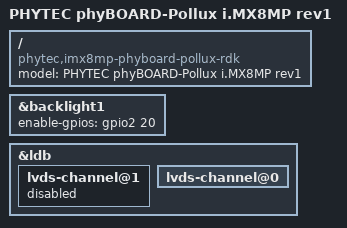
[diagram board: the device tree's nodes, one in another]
// SPDX-License-Identifier: GPL-2.0
/*
 * Copyright (C) 2021 PHYTEC Messtechnik GmbH
 * Author: Dominik Haller <d.haller@phytec.de>
 */

/dts-v1/;

#include "imx8mp-phycore-som.dtsi"
#include "imx8mp-phyboard-pollux.dtsi"
#include "imx8mp-phyboard-pollux-peb-wlbt-05.dtsi"

/ {
	model = "PHYTEC phyBOARD-Pollux i.MX8MP rev1";
	compatible = "phytec,imx8mp-phyboard-pollux-rdk",
		     "phytec,imx8mp-phycore-som", "fsl,imx8mp";
};

&backlight1 {
	enable-gpios = <&gpio2 20 GPIO_ACTIVE_HIGH>;
};

&ldb {
	lvds-channel@1 {
		status = "disabled";
	};

	lvds-channel@0 {
		status = "okay";
	};
};
